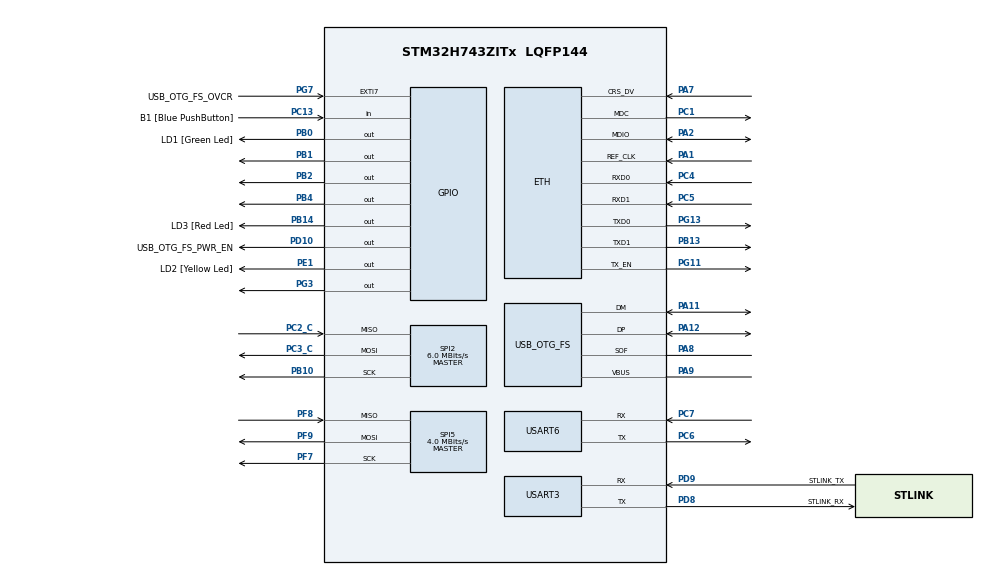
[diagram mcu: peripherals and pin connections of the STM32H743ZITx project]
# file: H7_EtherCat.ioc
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ETH.MediaInterface=HAL_ETH_RMII_MODE
Mcu.Family=STM32H7
Mcu.Name=STM32H743ZITx
Mcu.Package=LQFP144
NVIC.PriorityGroup=NVIC_PRIORITYGROUP_4
PA1.Mode=RMII
PA1.Signal=ETH_REF_CLK
PA11.Mode=Device_Only
PA11.Signal=USB_OTG_FS_DM
PA12.Mode=Device_Only
PA12.Signal=USB_OTG_FS_DP
PA2.Mode=RMII
PA2.Signal=ETH_MDIO
PA7.Mode=RMII
PA7.Signal=ETH_CRS_DV
PA8.Mode=Activate_SOF_FS
PA8.Signal=USB_OTG_FS_SOF
PA9.Mode=Activate_VBUS
PA9.Signal=USB_OTG_FS_VBUS
PB0.GPIO_Label=LD1 [Green Led]
PB0.Signal=GPIO_Output
PB1.Signal=GPIO_Output
PB10.Mode=Full_Duplex_Master
PB10.Signal=SPI2_SCK
PB13.Mode=RMII
PB13.Signal=ETH_TXD1
PB14.GPIO_Label=LD3 [Red Led]
PB14.Signal=GPIO_Output
PB2.Signal=GPIO_Output
PB4\ (NJTRST).Signal=GPIO_Output
PC1.Mode=RMII
PC1.Signal=ETH_MDC
PC13.GPIO_Label=B1 [Blue PushButton]
PC13.Signal=GPIO_Input
PC14-OSC32_IN\ (OSC32_IN).Mode=LSE-External-Oscillator
PC14-OSC32_IN\ (OSC32_IN).Signal=RCC_OSC32_IN
PC15-OSC32_OUT\ (OSC32_OUT).Mode=LSE-External-Oscillator
PC15-OSC32_OUT\ (OSC32_OUT).Signal=RCC_OSC32_OUT
PC2_C.Mode=Full_Duplex_Master
PC2_C.Signal=SPI2_MISO
PC3_C.Mode=Full_Duplex_Master
PC3_C.Signal=SPI2_MOSI
PC4.Mode=RMII
PC4.Signal=ETH_RXD0
PC5.Mode=RMII
PC5.Signal=ETH_RXD1
PC6.Mode=Asynchronous
PC6.Signal=USART6_TX
PC7.Mode=Asynchronous
PC7.Signal=USART6_RX
PD10.GPIO_Label=USB_OTG_FS_PWR_EN
PD10.Signal=GPIO_Output
PD8.GPIO_Label=STLINK_RX
PD8.Mode=Asynchronous
PD8.Signal=USART3_TX
PD9.GPIO_Label=STLINK_TX
PD9.Mode=Asynchronous
PD9.Signal=USART3_RX
PE1.GPIO_Label=LD2 [Yellow Led]
PE1.Signal=GPIO_Output
PF7.Mode=Full_Duplex_Master
PF7.Signal=SPI5_SCK
PF8.Mode=Full_Duplex_Master
PF8.Signal=SPI5_MISO
PF9.Mode=Full_Duplex_Master
PF9.Signal=SPI5_MOSI
PG11.Mode=RMII
PG11.Signal=ETH_TX_EN
PG13.Mode=RMII
PG13.Signal=ETH_TXD0
PG3.Signal=GPIO_Output
PG7.GPIO_Label=USB_OTG_FS_OVCR
PG7.Signal=GPXTI7
PH0-OSC_IN\ (PH0).Mode=HSE-External-Clock-Source
PH0-OSC_IN\ (PH0).Signal=RCC_OSC_IN
PH1-OSC_OUT\ (PH1).Mode=HSE-External-Clock-Source
PH1-OSC_OUT\ (PH1).Signal=RCC_OSC_OUT
ProjectManager.HeapSize=0x200
ProjectManager.StackSize=0x400
ProjectManager.TargetToolchain=SW4STM32
RCC.ADCFreq_Value=16125000
RCC.APB1Freq_Value=64000000
RCC.APB2Freq_Value=64000000
RCC.APB3Freq_Value=64000000
RCC.APB4Freq_Value=64000000
RCC.CortexFreq_Value=64000000
RCC.DIVM1=1
RCC.DIVN1=24
RCC.DIVQ1=4
RCC.HCLKFreq_Value=64000000
RCC.HSE_VALUE=8000000
RCC.PLLFRACN=0
RCC.SYSCLKFreq_VALUE=64000000
RCC.USBFreq_Value=48000000
SPI2.BaudRatePrescaler=SPI_BAUDRATEPRESCALER_8
SPI2.CalculateBaudRate=6.0 MBits/s
SPI2.DataSize=SPI_DATASIZE_8BIT
SPI2.Direction=SPI_DIRECTION_2LINES
SPI2.Mode=SPI_MODE_MASTER
SPI2.VirtualType=VM_MASTER
SPI5.BaudRatePrescaler=SPI_BAUDRATEPRESCALER_16
SPI5.CalculateBaudRate=4.0 MBits/s
SPI5.DataSize=SPI_DATASIZE_8BIT
SPI5.Direction=SPI_DIRECTION_2LINES
SPI5.Mode=SPI_MODE_MASTER
SPI5.VirtualType=VM_MASTER
USART3.VirtualMode-Asynchronous=VM_ASYNC
USART6.VirtualMode-Asynchronous=VM_ASYNC
USB_OTG_FS.VirtualMode=Device_Only
board=NUCLEO-H743ZI2

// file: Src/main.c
/* USER CODE BEGIN Header */
/**
  ******************************************************************************
  * @file           : main.c
  * @brief          : Main program body
  ******************************************************************************
  * @attention
  *
  * <h2><center>&copy; Copyright (c) 2019 STMicroelectronics.
  * All rights reserved.</center></h2>
  *
  * This software component is licensed by ST under BSD 3-Clause license,
  * the "License"; You may not use this file except in compliance with the
  * License. You may obtain a copy of the License at:
  *                        opensource.org/licenses/BSD-3-Clause
  *
  ******************************************************************************
  */
/* USER CODE END Header */

#include "main.h"
#include "string.h"

/* USER CODE BEGIN Includes */
#include <lan9252drv.h>
#include <lan9252.h>
/* USER CODE END Includes */

#if defined ( __ICCARM__ ) /*!< IAR Compiler */

#pragma location=0x30040000
ETH_DMADescTypeDef  DMARxDscrTab[ETH_RX_DESC_CNT]; /* Ethernet Rx DMA Descriptors */
#pragma location=0x30040060
ETH_DMADescTypeDef  DMATxDscrTab[ETH_TX_DESC_CNT]; /* Ethernet Tx DMA Descriptors */
#pragma location=0x30040200
uint8_t Rx_Buff[ETH_RX_DESC_CNT][ETH_MAX_PACKET_SIZE]; /* Ethernet Receive Buffers */

#elif defined ( __CC_ARM )  /* MDK ARM Compiler */

__attribute__((at(0x30040000))) ETH_DMADescTypeDef  DMARxDscrTab[ETH_RX_DESC_CNT]; /* Ethernet Rx DMA Descriptors */
__attribute__((at(0x30040060))) ETH_DMADescTypeDef  DMATxDscrTab[ETH_TX_DESC_CNT]; /* Ethernet Tx DMA Descriptors */
__attribute__((at(0x30040200))) uint8_t Rx_Buff[ETH_RX_DESC_CNT][ETH_MAX_PACKET_SIZE]; /* Ethernet Receive Buffer */

#elif defined ( __GNUC__ ) /* GNU Compiler */

ETH_DMADescTypeDef DMARxDscrTab[ETH_RX_DESC_CNT] __attribute__((section(".RxDecripSection"))); /* Ethernet Rx DMA Descriptors */
ETH_DMADescTypeDef DMATxDscrTab[ETH_TX_DESC_CNT] __attribute__((section(".TxDecripSection")));   /* Ethernet Tx DMA Descriptors */
uint8_t Rx_Buff[ETH_RX_DESC_CNT][ETH_MAX_PACKET_SIZE] __attribute__((section(".RxArraySection"))); /* Ethernet Receive Buffers */

#endif

ETH_TxPacketConfig TxConfig;

ETH_HandleTypeDef heth;

SPI_HandleTypeDef hspi2;
SPI_HandleTypeDef hspi5;

UART_HandleTypeDef huart3;
UART_HandleTypeDef huart6;

PCD_HandleTypeDef hpcd_USB_OTG_FS;

/* USER CODE BEGIN PV */
spiCTX context;
/* USER CODE END PV */

void SystemClock_Config(void);
static void MX_GPIO_Init(void);
static void MX_ETH_Init(void);
static void MX_USART3_UART_Init(void);
static void MX_USB_OTG_FS_PCD_Init(void);
static void MX_SPI5_Init(void);
static void MX_USART6_UART_Init(void);
static void MX_SPI2_Init(void);
/* USER CODE BEGIN PFP */
PROCBUFFER_OUT 	BufferOut;
PROCBUFFER_IN 	BufferIn;
/* USER CODE END PFP */

int main(void)
{
  /* USER CODE BEGIN 1 */
	context.uart 	= &huart6;
	context.spi 	= &hspi2;
	context.bIn 	= &BufferIn;
	context.bOut 	= &BufferOut;
  /* USER CODE END 1 */

  /* MCU Configuration--------------------------------------------------------*/

  /* Reset of all peripherals, Initializes the Flash interface and the Systick. */
  HAL_Init();

  /* Configure the system clock */
  SystemClock_Config();

  /* Initialize all configured peripherals */
  MX_GPIO_Init();
  MX_ETH_Init();
  MX_USART3_UART_Init();
  MX_USB_OTG_FS_PCD_Init();
  MX_SPI5_Init();
  MX_USART6_UART_Init();
  MX_SPI2_Init();
  /* USER CODE BEGIN 2 */

  init9252(&context);
  HAL_GPIO_WritePin(GPIOB, GPIO_PIN_2, GPIO_PIN_RESET);
  /* USER CODE END 2 */

  /* Infinite loop */
  /* USER CODE BEGIN WHILE */
  while (1)
  {
	  HAL_GPIO_WritePin(GPIOB, GPIO_PIN_2, GPIO_PIN_SET);
	  app(&context);
	  HAL_GPIO_WritePin(GPIOB, GPIO_PIN_2, GPIO_PIN_RESET);
    /* USER CODE END WHILE */

  }
}

void SystemClock_Config(void)
{
  RCC_OscInitTypeDef RCC_OscInitStruct = {0};
  RCC_ClkInitTypeDef RCC_ClkInitStruct = {0};
  RCC_PeriphCLKInitTypeDef PeriphClkInitStruct = {0};

  /** Supply configuration update enable
  */
  HAL_PWREx_ConfigSupply(PWR_LDO_SUPPLY);
  /** Configure the main internal regulator output voltage
  */
  __HAL_PWR_VOLTAGESCALING_CONFIG(PWR_REGULATOR_VOLTAGE_SCALE3);

  while(!__HAL_PWR_GET_FLAG(PWR_FLAG_VOSRDY)) {}
  /** Initializes the CPU, AHB and APB busses clocks
  */
  RCC_OscInitStruct.OscillatorType = RCC_OSCILLATORTYPE_HSI|RCC_OSCILLATORTYPE_HSE;
  RCC_OscInitStruct.HSEState = RCC_HSE_BYPASS;
  RCC_OscInitStruct.HSIState = RCC_HSI_DIV1;
  RCC_OscInitStruct.HSICalibrationValue = RCC_HSICALIBRATION_DEFAULT;
  RCC_OscInitStruct.PLL.PLLState = RCC_PLL_ON;
  RCC_OscInitStruct.PLL.PLLSource = RCC_PLLSOURCE_HSE;
  RCC_OscInitStruct.PLL.PLLM = 1;
  RCC_OscInitStruct.PLL.PLLN = 24;
  RCC_OscInitStruct.PLL.PLLP = 2;
  RCC_OscInitStruct.PLL.PLLQ = 4;
  RCC_OscInitStruct.PLL.PLLR = 2;
  RCC_OscInitStruct.PLL.PLLRGE = RCC_PLL1VCIRANGE_3;
  RCC_OscInitStruct.PLL.PLLVCOSEL = RCC_PLL1VCOWIDE;
  RCC_OscInitStruct.PLL.PLLFRACN = 0;
  if (HAL_RCC_OscConfig(&RCC_OscInitStruct) != HAL_OK)
  {
    Error_Handler();
  }
  /** Initializes the CPU, AHB and APB busses clocks
  */
  RCC_ClkInitStruct.ClockType = RCC_CLOCKTYPE_HCLK|RCC_CLOCKTYPE_SYSCLK
                              |RCC_CLOCKTYPE_PCLK1|RCC_CLOCKTYPE_PCLK2
                              |RCC_CLOCKTYPE_D3PCLK1|RCC_CLOCKTYPE_D1PCLK1;
  RCC_ClkInitStruct.SYSCLKSource = RCC_SYSCLKSOURCE_HSI;
  RCC_ClkInitStruct.SYSCLKDivider = RCC_SYSCLK_DIV1;
  RCC_ClkInitStruct.AHBCLKDivider = RCC_HCLK_DIV1;
  RCC_ClkInitStruct.APB3CLKDivider = RCC_APB3_DIV1;
  RCC_ClkInitStruct.APB1CLKDivider = RCC_APB1_DIV1;
  RCC_ClkInitStruct.APB2CLKDivider = RCC_APB2_DIV1;
  RCC_ClkInitStruct.APB4CLKDivider = RCC_APB4_DIV1;

  if (HAL_RCC_ClockConfig(&RCC_ClkInitStruct, FLASH_LATENCY_0) != HAL_OK)
  {
    Error_Handler();
  }
  PeriphClkInitStruct.PeriphClockSelection = RCC_PERIPHCLK_USART3|RCC_PERIPHCLK_USART6
                              |RCC_PERIPHCLK_SPI5|RCC_PERIPHCLK_SPI2
                              |RCC_PERIPHCLK_USB;
  PeriphClkInitStruct.Spi123ClockSelection = RCC_SPI123CLKSOURCE_PLL;
  PeriphClkInitStruct.Spi45ClockSelection = RCC_SPI45CLKSOURCE_D2PCLK1;
  PeriphClkInitStruct.Usart234578ClockSelection = RCC_USART234578CLKSOURCE_D2PCLK1;
  PeriphClkInitStruct.Usart16ClockSelection = RCC_USART16CLKSOURCE_D2PCLK2;
  PeriphClkInitStruct.UsbClockSelection = RCC_USBCLKSOURCE_PLL;
  if (HAL_RCCEx_PeriphCLKConfig(&PeriphClkInitStruct) != HAL_OK)
  {
    Error_Handler();
  }
  /** Enable USB Voltage detector
  */
  HAL_PWREx_EnableUSBVoltageDetector();
}

static void MX_ETH_Init(void)
{

   uint8_t MACAddr[6] ;

  heth.Instance = ETH;
  MACAddr[0] = 0x00;
  MACAddr[1] = 0x80;
  MACAddr[2] = 0xE1;
  MACAddr[3] = 0x00;
  MACAddr[4] = 0x00;
  MACAddr[5] = 0x00;
  heth.Init.MACAddr = &MACAddr[0];
  heth.Init.MediaInterface = HAL_ETH_RMII_MODE;
  heth.Init.TxDesc = DMATxDscrTab;
  heth.Init.RxDesc = DMARxDscrTab;
  heth.Init.RxBuffLen = 1524;

  if (HAL_ETH_Init(&heth) != HAL_OK)
  {
    Error_Handler();
  }

  memset(&TxConfig, 0 , sizeof(ETH_TxPacketConfig));
  TxConfig.Attributes = ETH_TX_PACKETS_FEATURES_CSUM | ETH_TX_PACKETS_FEATURES_CRCPAD;
  TxConfig.ChecksumCtrl = ETH_CHECKSUM_IPHDR_PAYLOAD_INSERT_PHDR_CALC;
  TxConfig.CRCPadCtrl = ETH_CRC_PAD_INSERT;

}

static void MX_SPI2_Init(void)
{

  /* SPI2 parameter configuration*/
  hspi2.Instance = SPI2;
  hspi2.Init.Mode = SPI_MODE_MASTER;
  hspi2.Init.Direction = SPI_DIRECTION_2LINES;
  hspi2.Init.DataSize = SPI_DATASIZE_8BIT;
  hspi2.Init.CLKPolarity = SPI_POLARITY_LOW;
  hspi2.Init.CLKPhase = SPI_PHASE_1EDGE;
  hspi2.Init.NSS = SPI_NSS_SOFT;
  hspi2.Init.BaudRatePrescaler = SPI_BAUDRATEPRESCALER_8;
  hspi2.Init.FirstBit = SPI_FIRSTBIT_MSB;
  hspi2.Init.TIMode = SPI_TIMODE_DISABLE;
  hspi2.Init.CRCCalculation = SPI_CRCCALCULATION_DISABLE;
  hspi2.Init.CRCPolynomial = 0x0;
  hspi2.Init.NSSPMode = SPI_NSS_PULSE_ENABLE;
  hspi2.Init.NSSPolarity = SPI_NSS_POLARITY_LOW;
  hspi2.Init.FifoThreshold = SPI_FIFO_THRESHOLD_01DATA;
  hspi2.Init.TxCRCInitializationPattern = SPI_CRC_INITIALIZATION_ALL_ZERO_PATTERN;
  hspi2.Init.RxCRCInitializationPattern = SPI_CRC_INITIALIZATION_ALL_ZERO_PATTERN;
  hspi2.Init.MasterSSIdleness = SPI_MASTER_SS_IDLENESS_00CYCLE;
  hspi2.Init.MasterInterDataIdleness = SPI_MASTER_INTERDATA_IDLENESS_00CYCLE;
  hspi2.Init.MasterReceiverAutoSusp = SPI_MASTER_RX_AUTOSUSP_DISABLE;
  hspi2.Init.MasterKeepIOState = SPI_MASTER_KEEP_IO_STATE_DISABLE;
  hspi2.Init.IOSwap = SPI_IO_SWAP_DISABLE;
  if (HAL_SPI_Init(&hspi2) != HAL_OK)
  {
    Error_Handler();
  }

}

static void MX_SPI5_Init(void)
{

  /* SPI5 parameter configuration*/
  hspi5.Instance = SPI5;
  hspi5.Init.Mode = SPI_MODE_MASTER;
  hspi5.Init.Direction = SPI_DIRECTION_2LINES;
  hspi5.Init.DataSize = SPI_DATASIZE_8BIT;
  hspi5.Init.CLKPolarity = SPI_POLARITY_LOW;
  hspi5.Init.CLKPhase = SPI_PHASE_1EDGE;
  hspi5.Init.NSS = SPI_NSS_SOFT;
  hspi5.Init.BaudRatePrescaler = SPI_BAUDRATEPRESCALER_16;
  hspi5.Init.FirstBit = SPI_FIRSTBIT_MSB;
  hspi5.Init.TIMode = SPI_TIMODE_DISABLE;
  hspi5.Init.CRCCalculation = SPI_CRCCALCULATION_DISABLE;
  hspi5.Init.CRCPolynomial = 0x0;
  hspi5.Init.NSSPMode = SPI_NSS_PULSE_ENABLE;
  hspi5.Init.NSSPolarity = SPI_NSS_POLARITY_LOW;
  hspi5.Init.FifoThreshold = SPI_FIFO_THRESHOLD_01DATA;
  hspi5.Init.TxCRCInitializationPattern = SPI_CRC_INITIALIZATION_ALL_ZERO_PATTERN;
  hspi5.Init.RxCRCInitializationPattern = SPI_CRC_INITIALIZATION_ALL_ZERO_PATTERN;
  hspi5.Init.MasterSSIdleness = SPI_MASTER_SS_IDLENESS_00CYCLE;
  hspi5.Init.MasterInterDataIdleness = SPI_MASTER_INTERDATA_IDLENESS_00CYCLE;
  hspi5.Init.MasterReceiverAutoSusp = SPI_MASTER_RX_AUTOSUSP_DISABLE;
  hspi5.Init.MasterKeepIOState = SPI_MASTER_KEEP_IO_STATE_DISABLE;
  hspi5.Init.IOSwap = SPI_IO_SWAP_DISABLE;
  if (HAL_SPI_Init(&hspi5) != HAL_OK)
  {
    Error_Handler();
  }

}

static void MX_USART3_UART_Init(void)
{

  huart3.Instance = USART3;
  huart3.Init.BaudRate = 115200;
  huart3.Init.WordLength = UART_WORDLENGTH_8B;
  huart3.Init.StopBits = UART_STOPBITS_1;
  huart3.Init.Parity = UART_PARITY_NONE;
  huart3.Init.Mode = UART_MODE_TX_RX;
  huart3.Init.HwFlowCtl = UART_HWCONTROL_NONE;
  huart3.Init.OverSampling = UART_OVERSAMPLING_16;
  huart3.Init.OneBitSampling = UART_ONE_BIT_SAMPLE_DISABLE;
  huart3.Init.ClockPrescaler = UART_PRESCALER_DIV1;
  huart3.AdvancedInit.AdvFeatureInit = UART_ADVFEATURE_NO_INIT;
  if (HAL_UART_Init(&huart3) != HAL_OK)
  {
    Error_Handler();
  }
  if (HAL_UARTEx_SetTxFifoThreshold(&huart3, UART_TXFIFO_THRESHOLD_1_8) != HAL_OK)
  {
    Error_Handler();
  }
  if (HAL_UARTEx_SetRxFifoThreshold(&huart3, UART_RXFIFO_THRESHOLD_1_8) != HAL_OK)
  {
    Error_Handler();
  }
  if (HAL_UARTEx_DisableFifoMode(&huart3) != HAL_OK)
  {
    Error_Handler();
  }

}

static void MX_USART6_UART_Init(void)
{

  huart6.Instance = USART6;
  huart6.Init.BaudRate = 115200;
  huart6.Init.WordLength = UART_WORDLENGTH_8B;
  huart6.Init.StopBits = UART_STOPBITS_1;
  huart6.Init.Parity = UART_PARITY_NONE;
  huart6.Init.Mode = UART_MODE_TX_RX;
  huart6.Init.HwFlowCtl = UART_HWCONTROL_NONE;
  huart6.Init.OverSampling = UART_OVERSAMPLING_16;
  huart6.Init.OneBitSampling = UART_ONE_BIT_SAMPLE_DISABLE;
  huart6.Init.ClockPrescaler = UART_PRESCALER_DIV1;
  huart6.AdvancedInit.AdvFeatureInit = UART_ADVFEATURE_NO_INIT;
  if (HAL_UART_Init(&huart6) != HAL_OK)
  {
    Error_Handler();
  }
  if (HAL_UARTEx_SetTxFifoThreshold(&huart6, UART_TXFIFO_THRESHOLD_1_8) != HAL_OK)
  {
    Error_Handler();
  }
  if (HAL_UARTEx_SetRxFifoThreshold(&huart6, UART_RXFIFO_THRESHOLD_1_8) != HAL_OK)
  {
    Error_Handler();
  }
  if (HAL_UARTEx_DisableFifoMode(&huart6) != HAL_OK)
  {
    Error_Handler();
  }

}

static void MX_USB_OTG_FS_PCD_Init(void)
{

  hpcd_USB_OTG_FS.Instance = USB_OTG_FS;
  hpcd_USB_OTG_FS.Init.dev_endpoints = 9;
  hpcd_USB_OTG_FS.Init.speed = PCD_SPEED_FULL;
  hpcd_USB_OTG_FS.Init.dma_enable = DISABLE;
  hpcd_USB_OTG_FS.Init.phy_itface = PCD_PHY_EMBEDDED;
  hpcd_USB_OTG_FS.Init.Sof_enable = ENABLE;
  hpcd_USB_OTG_FS.Init.low_power_enable = DISABLE;
  hpcd_USB_OTG_FS.Init.lpm_enable = DISABLE;
  hpcd_USB_OTG_FS.Init.battery_charging_enable = ENABLE;
  hpcd_USB_OTG_FS.Init.vbus_sensing_enable = ENABLE;
  hpcd_USB_OTG_FS.Init.use_dedicated_ep1 = DISABLE;
  if (HAL_PCD_Init(&hpcd_USB_OTG_FS) != HAL_OK)
  {
    Error_Handler();
  }

}

static void MX_GPIO_Init(void)
{
  GPIO_InitTypeDef GPIO_InitStruct = {0};

  /* GPIO Ports Clock Enable */
  __HAL_RCC_GPIOC_CLK_ENABLE();
  __HAL_RCC_GPIOF_CLK_ENABLE();
  __HAL_RCC_GPIOH_CLK_ENABLE();
  __HAL_RCC_GPIOA_CLK_ENABLE();
  __HAL_RCC_GPIOB_CLK_ENABLE();
  __HAL_RCC_GPIOD_CLK_ENABLE();
  __HAL_RCC_GPIOG_CLK_ENABLE();
  __HAL_RCC_GPIOE_CLK_ENABLE();

  /*Configure GPIO pin Output Level */
  HAL_GPIO_WritePin(GPIOB, LD1_Pin|GPIO_PIN_1|GPIO_PIN_2|LD3_Pin
                          |GPIO_PIN_4, GPIO_PIN_RESET);

  /*Configure GPIO pin Output Level */
  HAL_GPIO_WritePin(USB_OTG_FS_PWR_EN_GPIO_Port, USB_OTG_FS_PWR_EN_Pin, GPIO_PIN_RESET);

  /*Configure GPIO pin Output Level */
  HAL_GPIO_WritePin(GPIOG, GPIO_PIN_3, GPIO_PIN_RESET);

  /*Configure GPIO pin Output Level */
  HAL_GPIO_WritePin(LD2_GPIO_Port, LD2_Pin, GPIO_PIN_RESET);

  /*Configure GPIO pin : B1_Pin */
  GPIO_InitStruct.Pin = B1_Pin;
  GPIO_InitStruct.Mode = GPIO_MODE_INPUT;
  GPIO_InitStruct.Pull = GPIO_NOPULL;
  HAL_GPIO_Init(B1_GPIO_Port, &GPIO_InitStruct);

  /*Configure GPIO pins : LD1_Pin PB1 PB2 LD3_Pin
                           PB4 */
  GPIO_InitStruct.Pin = LD1_Pin|GPIO_PIN_1|GPIO_PIN_2|LD3_Pin
                          |GPIO_PIN_4;
  GPIO_InitStruct.Mode = GPIO_MODE_OUTPUT_PP;
  GPIO_InitStruct.Pull = GPIO_NOPULL;
  GPIO_InitStruct.Speed = GPIO_SPEED_FREQ_LOW;
  HAL_GPIO_Init(GPIOB, &GPIO_InitStruct);

  /*Configure GPIO pin : USB_OTG_FS_PWR_EN_Pin */
  GPIO_InitStruct.Pin = USB_OTG_FS_PWR_EN_Pin;
  GPIO_InitStruct.Mode = GPIO_MODE_OUTPUT_PP;
  GPIO_InitStruct.Pull = GPIO_NOPULL;
  GPIO_InitStruct.Speed = GPIO_SPEED_FREQ_LOW;
  HAL_GPIO_Init(USB_OTG_FS_PWR_EN_GPIO_Port, &GPIO_InitStruct);

  /*Configure GPIO pin : PG3 */
  GPIO_InitStruct.Pin = GPIO_PIN_3;
  GPIO_InitStruct.Mode = GPIO_MODE_OUTPUT_PP;
  GPIO_InitStruct.Pull = GPIO_NOPULL;
  GPIO_InitStruct.Speed = GPIO_SPEED_FREQ_LOW;
  HAL_GPIO_Init(GPIOG, &GPIO_InitStruct);

  /*Configure GPIO pin : USB_OTG_FS_OVCR_Pin */
  GPIO_InitStruct.Pin = USB_OTG_FS_OVCR_Pin;
  GPIO_InitStruct.Mode = GPIO_MODE_IT_RISING;
  GPIO_InitStruct.Pull = GPIO_NOPULL;
  HAL_GPIO_Init(USB_OTG_FS_OVCR_GPIO_Port, &GPIO_InitStruct);

  /*Configure GPIO pin : LD2_Pin */
  GPIO_InitStruct.Pin = LD2_Pin;
  GPIO_InitStruct.Mode = GPIO_MODE_OUTPUT_PP;
  GPIO_InitStruct.Pull = GPIO_NOPULL;
  GPIO_InitStruct.Speed = GPIO_SPEED_FREQ_LOW;
  HAL_GPIO_Init(LD2_GPIO_Port, &GPIO_InitStruct);

}

void Error_Handler(void)
{
}

/************************ (C) COPYRIGHT STMicroelectronics *****END OF FILE****/
